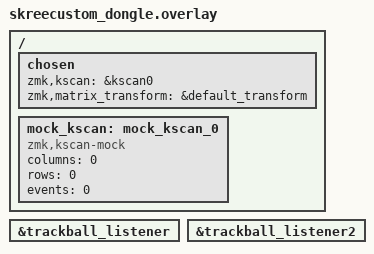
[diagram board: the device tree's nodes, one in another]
#include "skreecustom.dtsi"

/ {
     chosen {
        zmk,kscan = &kscan0;
        zmk,matrix_transform = &default_transform;
   };

  mock_kscan: mock_kscan_0 {
    compatible = "zmk,kscan-mock";
    columns = <0>;
    rows = <0>;
    events = <0>;
  };
};

&trackball_listener {
  status = "okay";
};

&trackball_listener2 {
  status = "okay";
};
